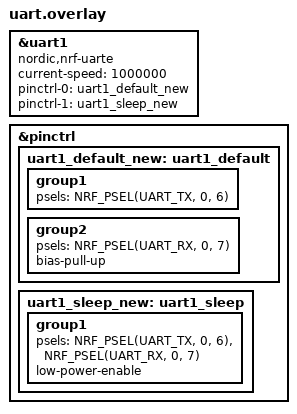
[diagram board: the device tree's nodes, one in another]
// To get started, press Ctrl+Space to bring up the completion menu and view the available nodes.

// You can also use the buttons in the sidebar to perform actions on nodes.
// Actions currently available include:

// * Enabling / disabling the node
// * Adding the bus to a bus
// * Removing the node
// * Connecting ADC channels

// For more help, browse the DeviceTree documentation at https://docs.zephyrproject.org/latest/guides/dts/index.html
// You can also visit the nRF DeviceTree extension documentation at https://docs.nordicsemi.com/bundle/nrf-connect-vscode/page/guides/ncs_configure_app.html#devicetree-support-in-the-extension

uart: &uart1 {
	status = "okay";
	compatible = "nordic,nrf-uarte";
	current-speed = <1000000>;
	pinctrl-0 = <&uart1_default_new>;
	pinctrl-1 = <&uart1_sleep_new>;
};

&pinctrl {
	uart1_default_new: uart1_default {
		group1 {
			psels = <NRF_PSEL(UART_TX, 0, 6)>;
		};
		group2 {
			psels = <NRF_PSEL(UART_RX, 0, 7)>;
			bias-pull-up;
		};
	};

	uart1_sleep_new: uart1_sleep {
		group1 {
			psels = <NRF_PSEL(UART_TX, 0, 6)>,
				<NRF_PSEL(UART_RX, 0, 7)>;
			low-power-enable;
		};
	};

};
